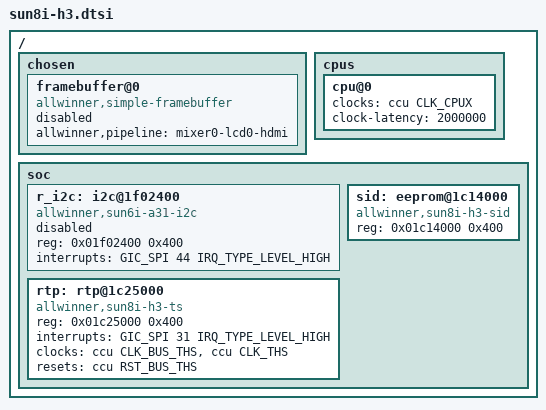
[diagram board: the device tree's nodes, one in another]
/* $NetBSD: sun8i-h3.dtsi,v 1.6.2.2 2017/12/03 11:35:52 jdolecek Exp $ */

/*-
 * Copyright (c) 2017 Jared McNeill <jmcneill@invisible.ca>
 * All rights reserved.
 *
 * Redistribution and use in source and binary forms, with or without
 * modification, are permitted provided that the following conditions
 * are met:
 * 1. Redistributions of source code must retain the above copyright
 *    notice, this list of conditions and the following disclaimer.
 * 2. Redistributions in binary form must reproduce the above copyright
 *    notice, this list of conditions and the following disclaimer in the
 *    documentation and/or other materials provided with the distribution.
 *
 * THIS SOFTWARE IS PROVIDED BY THE AUTHOR ``AS IS'' AND ANY EXPRESS OR
 * IMPLIED WARRANTIES, INCLUDING, BUT NOT LIMITED TO, THE IMPLIED WARRANTIES
 * OF MERCHANTABILITY AND FITNESS FOR A PARTICULAR PURPOSE ARE DISCLAIMED.
 * IN NO EVENT SHALL THE AUTHOR BE LIABLE FOR ANY DIRECT, INDIRECT,
 * INCIDENTAL, SPECIAL, EXEMPLARY, OR CONSEQUENTIAL DAMAGES (INCLUDING,
 * BUT NOT LIMITED TO, PROCUREMENT OF SUBSTITUTE GOODS OR SERVICES;
 * LOSS OF USE, DATA, OR PROFITS; OR BUSINESS INTERRUPTION) HOWEVER CAUSED
 * AND ON ANY THEORY OF LIABILITY, WHETHER IN CONTRACT, STRICT LIABILITY,
 * OR TORT (INCLUDING NEGLIGENCE OR OTHERWISE) ARISING IN ANY WAY
 * OUT OF THE USE OF THIS SOFTWARE, EVEN IF ADVISED OF THE POSSIBILITY OF
 * SUCH DAMAGE.
 */

/ {
	chosen {
		#address-cells = <1>;
		#size-cells = <1>;
		ranges;

		framebuffer@0 {
			compatible = "allwinner,simple-framebuffer",
				     "simple-framebuffer";
			allwinner,pipeline = "mixer0-lcd0-hdmi";
			status = "disabled";
		};
	};

	cpus {
		cpu@0 {
			clocks = <&ccu CLK_CPUX>;
			clock-latency = <2000000>;
		};
	};

	soc {
		r_i2c: i2c@1f02400 {
			compatible = "allwinner,sun6i-a31-i2c";
			reg = <0x01f02400 0x400>;
			interrupts = <GIC_SPI 44 IRQ_TYPE_LEVEL_HIGH>;
			status = "disabled";
			#address-cells = <1>;
			#size-cells = <0>;
		};

		sid: eeprom@1c14000 {
			compatible = "allwinner,sun8i-h3-sid";
			reg = <0x01c14000 0x400>;
		};

		rtp: rtp@1c25000 {
			compatible = "allwinner,sun8i-h3-ts";
			reg = <0x01c25000 0x400>;
			interrupts = <GIC_SPI 31 IRQ_TYPE_LEVEL_HIGH>;
			clocks = <&ccu CLK_BUS_THS>, <&ccu CLK_THS>;
			clock-names = "ahb", "ths";
			resets = <&ccu RST_BUS_THS>;
			#thermal-sensor-cells = <0>;
		};
	};
};
